# CONTROLSS_ADC3_RESULT_CONTROLSS_ADC3_RESULT register map
Vendor: Texas Instruments
Peripheral module from a debugger description file (folder AM263).
Registers are 16-bit, read-only, reset 0x0 unless marked. A register's access mark holds for its fields unless they carry their own. Offsets are as the file gives them; lines under a group give offsets from that group; [hi:lo] are bit positions; {n}, {i} and the like mark numbered series; 'fields as' and 'values as' point back to an identical list; <NAME> marks a mode.

## CONTROLSS_ADC3_RESULT_CONTROLSS_ADC3_RESULT
{0x0+2i} CONTROLSS_ADC3_RESULT_ADCRESULT{i} (i=0..15)
  [15:0] RESULT — ADC Result {i} 16-bit ADC result. After the ADC completes a conversion of SOC{i}, the digital result is placed in this bit field.
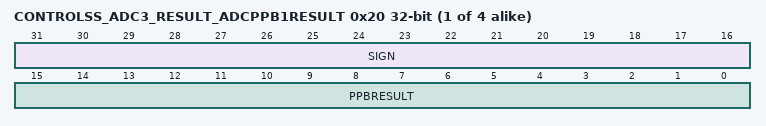
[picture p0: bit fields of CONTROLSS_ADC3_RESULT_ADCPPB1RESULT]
{0x1C+4i} CONTROLSS_ADC3_RESULT_ADCPPB{i}RESULT 32-bit (i=1..4)
  [31:16] SIGN — Sign Extended Bits. These bits reflect the same value as bit 16. NOTE: If the conversion associated with this Post Processing Block is a 12-bit conversion, the SIGN bits extend down to bit 12, and all reflect the same value as bit 12.
  [15:0] PPBRESULT — ADC Post Processing Block Result {i} The result of the offset/reference subtraction post conversion processing is stored in this register. If ADCINTFLG is polled in reading PPBRESULT, user needs to add a NOP instruction to ensure that post conversion processing is populated in this register. NOTE: If the conversion associated with this Post Processing Block is a 12-bit conversion, the PPBRESULT bits are limited to bits 12:0.
